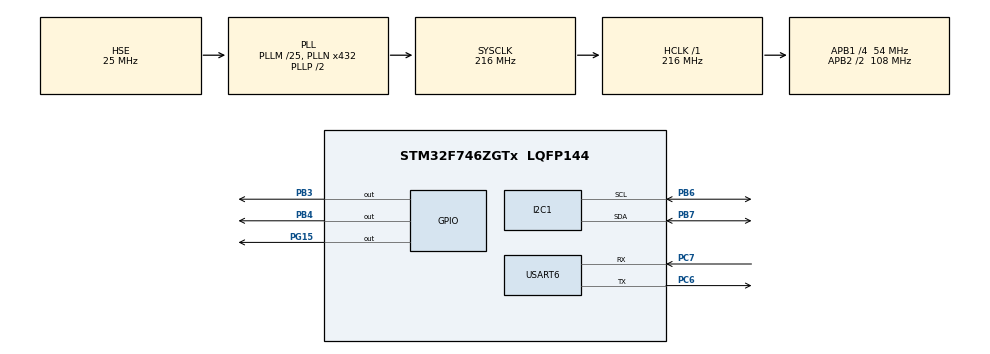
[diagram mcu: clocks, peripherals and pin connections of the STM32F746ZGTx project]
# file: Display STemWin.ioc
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I2C1.Timing=0x20404768
Mcu.Family=STM32F7
Mcu.Name=STM32F746ZGTx
Mcu.Package=LQFP144
NVIC.PriorityGroup=NVIC_PRIORITYGROUP_4
PB3.Signal=GPIO_Output
PB4.Signal=GPIO_Output
PB6.Mode=I2C
PB6.Signal=I2C1_SCL
PB7.Mode=I2C
PB7.Signal=I2C1_SDA
PC6.Mode=Asynchronous
PC6.Signal=USART6_TX
PC7.Mode=Asynchronous
PC7.Signal=USART6_RX
PG15.Signal=GPIO_Output
PH0/OSC_IN.Mode=HSE-External-Oscillator
PH0/OSC_IN.Signal=RCC_OSC_IN
PH1/OSC_OUT.Mode=HSE-External-Oscillator
PH1/OSC_OUT.Signal=RCC_OSC_OUT
ProjectManager.HeapSize=0x200
ProjectManager.StackSize=0x400
ProjectManager.TargetToolchain=SW4STM32
RCC.AHBFreq_Value=216000000
RCC.APB1CLKDivider=RCC_HCLK_DIV4
RCC.APB1Freq_Value=54000000
RCC.APB1TimFreq_Value=108000000
RCC.APB2CLKDivider=RCC_HCLK_DIV2
RCC.APB2Freq_Value=108000000
RCC.APB2TimFreq_Value=216000000
RCC.CortexFreq_Value=216000000
RCC.HCLKFreq_Value=216000000
RCC.HSE_VALUE=25000000
RCC.HSI_VALUE=16000000
RCC.LSE_VALUE=32768
RCC.PLLM=25
RCC.PLLN=432
RCC.PLLSourceVirtual=RCC_PLLSOURCE_HSE
RCC.SYSCLKFreq_VALUE=216000000
RCC.SYSCLKSource=RCC_SYSCLKSOURCE_PLLCLK
RCC.USBFreq_Value=216000000
RCC.VCOOutputFreq_Value=432000000
USART6.VirtualMode-Asynchronous=VM_ASYNC
board=custom

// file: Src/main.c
/**
  ******************************************************************************
  * @file           : main.c
  * @brief          : Main program body
  ******************************************************************************
  ** This notice applies to any and all portions of this file
  * that are not between comment pairs USER CODE BEGIN and
  * USER CODE END. Other portions of this file, whether
  * inserted by the user or by software development tools
  * are owned by their respective copyright owners.
  *
  * COPYRIGHT(c) 2018 STMicroelectronics
  *
  * Redistribution and use in source and binary forms, with or without modification,
  * are permitted provided that the following conditions are met:
  *   1. Redistributions of source code must retain the above copyright notice,
  *      this list of conditions and the following disclaimer.
  *   2. Redistributions in binary form must reproduce the above copyright notice,
  *      this list of conditions and the following disclaimer in the documentation
  *      and/or other materials provided with the distribution.
  *   3. Neither the name of STMicroelectronics nor the names of its contributors
  *      may be used to endorse or promote products derived from this software
  *      without specific prior written permission.
  *
  * THIS SOFTWARE IS PROVIDED BY THE COPYRIGHT HOLDERS AND CONTRIBUTORS "AS IS"
  * AND ANY EXPRESS OR IMPLIED WARRANTIES, INCLUDING, BUT NOT LIMITED TO, THE
  * IMPLIED WARRANTIES OF MERCHANTABILITY AND FITNESS FOR A PARTICULAR PURPOSE ARE
  * DISCLAIMED. IN NO EVENT SHALL THE COPYRIGHT HOLDER OR CONTRIBUTORS BE LIABLE
  * FOR ANY DIRECT, INDIRECT, INCIDENTAL, SPECIAL, EXEMPLARY, OR CONSEQUENTIAL
  * DAMAGES (INCLUDING, BUT NOT LIMITED TO, PROCUREMENT OF SUBSTITUTE GOODS OR
  * SERVICES; LOSS OF USE, DATA, OR PROFITS; OR BUSINESS INTERRUPTION) HOWEVER
  * CAUSED AND ON ANY THEORY OF LIABILITY, WHETHER IN CONTRACT, STRICT LIABILITY,
  * OR TORT (INCLUDING NEGLIGENCE OR OTHERWISE) ARISING IN ANY WAY OUT OF THE USE
  * OF THIS SOFTWARE, EVEN IF ADVISED OF THE POSSIBILITY OF SUCH DAMAGE.
  *
  ******************************************************************************
  */
#include "main.h"
//#include "stm32f7xx_hal.h"

/* USER CODE BEGIN Includes */

#include "AS7261Sensor/ASMaster.h"

/* USER CODE END Includes */

I2C_HandleTypeDef hi2c1;

//extern UART_HandleTypeDef huart6;

/* USER CODE BEGIN PV */
/* Private variables ---------------------------------------------------------*/

WM_HWIN hWin;
char message[20];
/* USER CODE END PV */

void SystemClock_Config(void);
static void MX_GPIO_Init(void);
static void MX_I2C1_Init(void);
static void MX_USART6_UART_Init(void);

/* USER CODE BEGIN PFP */
/* Private function prototypes -----------------------------------------------*/
extern volatile GUI_TIMER_TIME OS_TimeMS;
void HAL_SYSTICK_Callback(void)
{
	OS_TimeMS++;
}

/* USER CODE END PFP */

int main(void)
{

  /* MCU Configuration----------------------------------------------------------*/

  /* Reset of all peripherals, Initializes the Flash interface and the Systick. */
  HAL_Init();

  /* Configure the system clock */
  SystemClock_Config();

  /* Initialize all configured peripherals */
  MX_GPIO_Init();
  MX_I2C1_Init();
  MX_USART6_UART_Init();
  /* USER CODE BEGIN 2 */
  Init_LCD_GPIO();
  Init_TOUCH_GPIO(hi2c1);

  WM_SetCreateFlags(WM_CF_MEMDEV); // eliminise flickering
  GUI_Init();
  GUI_Clear();

  AS7261_Sensor();

  /* USER CODE END 2 */

  /* Infinite loop */
  while (1)
  {

  }

}

void SystemClock_Config(void)
{

  RCC_OscInitTypeDef RCC_OscInitStruct;
  RCC_ClkInitTypeDef RCC_ClkInitStruct;
  RCC_PeriphCLKInitTypeDef PeriphClkInitStruct;

    /**Configure the main internal regulator output voltage
    */
  __HAL_RCC_PWR_CLK_ENABLE();

  __HAL_PWR_VOLTAGESCALING_CONFIG(PWR_REGULATOR_VOLTAGE_SCALE1);

    /**Initializes the CPU, AHB and APB busses clocks
    */
  RCC_OscInitStruct.OscillatorType = RCC_OSCILLATORTYPE_HSE;
  RCC_OscInitStruct.HSEState = RCC_HSE_ON;
  RCC_OscInitStruct.PLL.PLLState = RCC_PLL_ON;
  RCC_OscInitStruct.PLL.PLLSource = RCC_PLLSOURCE_HSE;
  RCC_OscInitStruct.PLL.PLLM = 25;
  RCC_OscInitStruct.PLL.PLLN = 432;
  RCC_OscInitStruct.PLL.PLLP = RCC_PLLP_DIV2;
  RCC_OscInitStruct.PLL.PLLQ = 2;
  if (HAL_RCC_OscConfig(&RCC_OscInitStruct) != HAL_OK)
  {
    _Error_Handler(__FILE__, __LINE__);
  }

    /**Activate the Over-Drive mode
    */
  if (HAL_PWREx_EnableOverDrive() != HAL_OK)
  {
    _Error_Handler(__FILE__, __LINE__);
  }

    /**Initializes the CPU, AHB and APB busses clocks
    */
  RCC_ClkInitStruct.ClockType = RCC_CLOCKTYPE_HCLK|RCC_CLOCKTYPE_SYSCLK
                              |RCC_CLOCKTYPE_PCLK1|RCC_CLOCKTYPE_PCLK2;
  RCC_ClkInitStruct.SYSCLKSource = RCC_SYSCLKSOURCE_PLLCLK;
  RCC_ClkInitStruct.AHBCLKDivider = RCC_SYSCLK_DIV1;
  RCC_ClkInitStruct.APB1CLKDivider = RCC_HCLK_DIV4;
  RCC_ClkInitStruct.APB2CLKDivider = RCC_HCLK_DIV2;

  if (HAL_RCC_ClockConfig(&RCC_ClkInitStruct, FLASH_LATENCY_7) != HAL_OK)
  {
    _Error_Handler(__FILE__, __LINE__);
  }

  PeriphClkInitStruct.PeriphClockSelection = RCC_PERIPHCLK_USART6|RCC_PERIPHCLK_I2C1;
  PeriphClkInitStruct.Usart6ClockSelection = RCC_USART6CLKSOURCE_PCLK2;
  PeriphClkInitStruct.I2c1ClockSelection = RCC_I2C1CLKSOURCE_PCLK1;
  if (HAL_RCCEx_PeriphCLKConfig(&PeriphClkInitStruct) != HAL_OK)
  {
    _Error_Handler(__FILE__, __LINE__);
  }

    /**Configure the Systick interrupt time
    */
  HAL_SYSTICK_Config(HAL_RCC_GetHCLKFreq()/1000);

    /**Configure the Systick
    */
  HAL_SYSTICK_CLKSourceConfig(SYSTICK_CLKSOURCE_HCLK);

  /* SysTick_IRQn interrupt configuration */
  HAL_NVIC_SetPriority(SysTick_IRQn, 0, 0);
}

/* I2C1 init function */
static void MX_I2C1_Init(void)
{

  hi2c1.Instance = I2C1;
  hi2c1.Init.Timing = 0x20404768;
  hi2c1.Init.OwnAddress1 = 0;
  hi2c1.Init.AddressingMode = I2C_ADDRESSINGMODE_7BIT;
  hi2c1.Init.DualAddressMode = I2C_DUALADDRESS_DISABLE;
  hi2c1.Init.OwnAddress2 = 0;
  hi2c1.Init.OwnAddress2Masks = I2C_OA2_NOMASK;
  hi2c1.Init.GeneralCallMode = I2C_GENERALCALL_DISABLE;
  hi2c1.Init.NoStretchMode = I2C_NOSTRETCH_DISABLE;
  if (HAL_I2C_Init(&hi2c1) != HAL_OK)
  {
    _Error_Handler(__FILE__, __LINE__);
  }

    /**Configure Analogue filter
    */
  if (HAL_I2CEx_ConfigAnalogFilter(&hi2c1, I2C_ANALOGFILTER_ENABLE) != HAL_OK)
  {
    _Error_Handler(__FILE__, __LINE__);
  }

    /**Configure Digital filter
    */
  if (HAL_I2CEx_ConfigDigitalFilter(&hi2c1, 0) != HAL_OK)
  {
    _Error_Handler(__FILE__, __LINE__);
  }

}

/* USART6 init function */
static void MX_USART6_UART_Init(void)
{

  huart6.Instance = USART6;
  huart6.Init.BaudRate = 115200;
  huart6.Init.WordLength = UART_WORDLENGTH_8B;
  huart6.Init.StopBits = UART_STOPBITS_1;
  huart6.Init.Parity = UART_PARITY_NONE;
  huart6.Init.Mode = UART_MODE_TX_RX;
  huart6.Init.HwFlowCtl = UART_HWCONTROL_NONE;
  huart6.Init.OverSampling = UART_OVERSAMPLING_16;
  huart6.Init.OneBitSampling = UART_ONE_BIT_SAMPLE_DISABLE;
  huart6.AdvancedInit.AdvFeatureInit = UART_ADVFEATURE_NO_INIT;
  if (HAL_UART_Init(&huart6) != HAL_OK)
  {
    _Error_Handler(__FILE__, __LINE__);
  }

}

/** Configure pins as
        * Analog
        * Input
        * Output
        * EVENT_OUT
        * EXTI
*/
static void MX_GPIO_Init(void)
{

  GPIO_InitTypeDef GPIO_InitStruct;

  /* GPIO Ports Clock Enable */
  __HAL_RCC_GPIOH_CLK_ENABLE();
  __HAL_RCC_GPIOC_CLK_ENABLE();
  __HAL_RCC_GPIOG_CLK_ENABLE();
  __HAL_RCC_GPIOB_CLK_ENABLE();

  /*Configure GPIO pin Output Level */
  HAL_GPIO_WritePin(GPIOG, GPIO_PIN_15, GPIO_PIN_RESET);

  /*Configure GPIO pin Output Level */
  HAL_GPIO_WritePin(GPIOB, GPIO_PIN_3|GPIO_PIN_4, GPIO_PIN_RESET);

  /*Configure GPIO pin : PG15 */
  GPIO_InitStruct.Pin = GPIO_PIN_15;
  GPIO_InitStruct.Mode = GPIO_MODE_OUTPUT_PP;
  GPIO_InitStruct.Pull = GPIO_NOPULL;
  GPIO_InitStruct.Speed = GPIO_SPEED_FREQ_LOW;
  HAL_GPIO_Init(GPIOG, &GPIO_InitStruct);

  /*Configure GPIO pins : PB3 PB4 */
  GPIO_InitStruct.Pin = GPIO_PIN_3|GPIO_PIN_4;
  GPIO_InitStruct.Mode = GPIO_MODE_OUTPUT_PP;
  GPIO_InitStruct.Pull = GPIO_NOPULL;
  GPIO_InitStruct.Speed = GPIO_SPEED_FREQ_LOW;
  HAL_GPIO_Init(GPIOB, &GPIO_InitStruct);

}

void _Error_Handler(char *file, int line)
{
  while(1)
  {
  }
}

/************************ (C) COPYRIGHT STMicroelectronics *****END OF FILE****/
